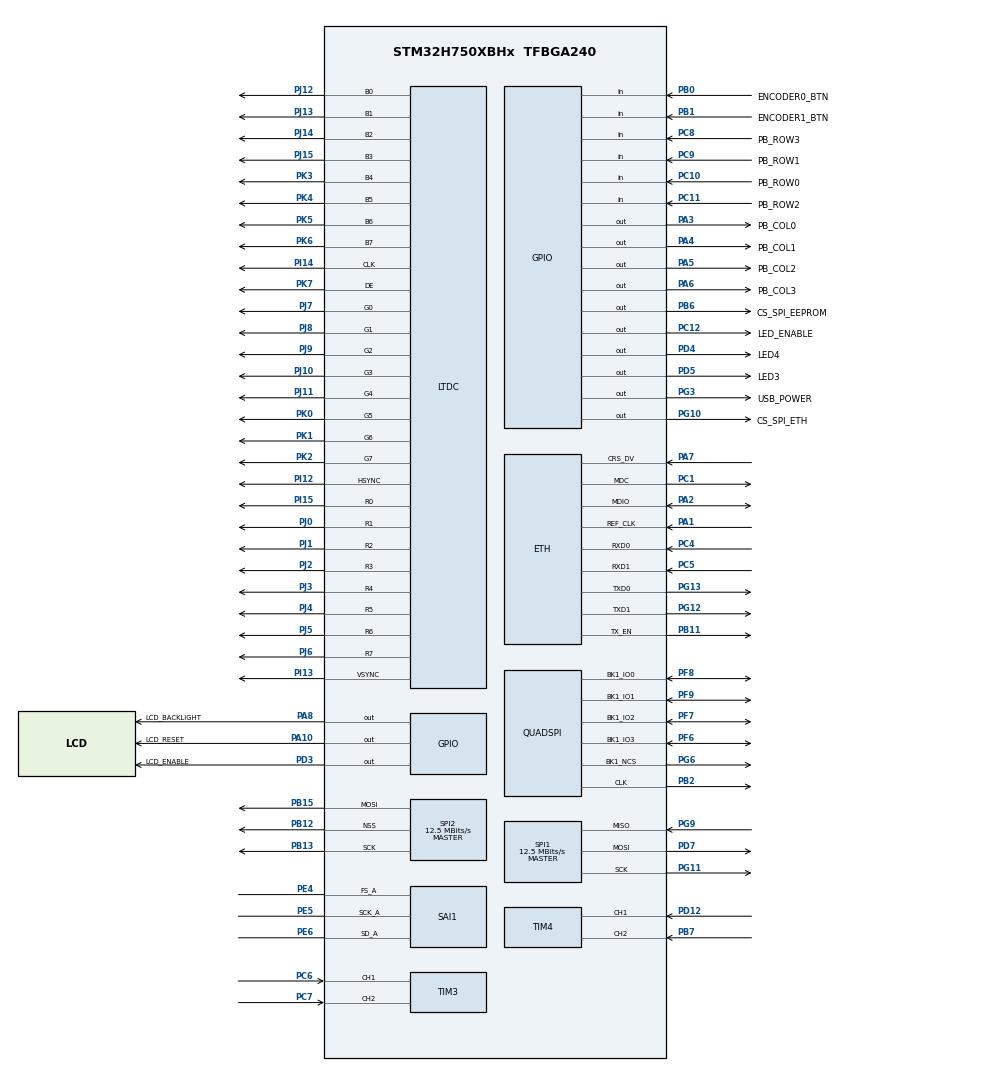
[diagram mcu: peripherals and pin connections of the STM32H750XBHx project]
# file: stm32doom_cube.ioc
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CORTEX_M7.MPU_Control=__NULL
CORTEX_M7.default_mode_Activation=1
DMA2D.ColorMode=DMA2D_OUTPUT_RGB888
DMA2D.Mode=DMA2D_M2M
Dma.Request0=SAI1_A
Dma.SAI1_A.0.Direction=DMA_MEMORY_TO_PERIPH
Dma.SAI1_A.0.EventEnable=DISABLE
Dma.SAI1_A.0.FIFOMode=DMA_FIFOMODE_DISABLE
Dma.SAI1_A.0.Instance=DMA1_Stream4
Dma.SAI1_A.0.MemDataAlignment=DMA_MDATAALIGN_WORD
Dma.SAI1_A.0.MemInc=DMA_MINC_ENABLE
Dma.SAI1_A.0.Mode=DMA_CIRCULAR
Dma.SAI1_A.0.PeriphDataAlignment=DMA_PDATAALIGN_WORD
Dma.SAI1_A.0.PeriphInc=DMA_PINC_DISABLE
Dma.SAI1_A.0.Polarity=HAL_DMAMUX_REQ_GEN_RISING
Dma.SAI1_A.0.Priority=DMA_PRIORITY_HIGH
Dma.SAI1_A.0.RequestNumber=1
Dma.SAI1_A.0.SignalID=NONE
Dma.SAI1_A.0.SyncEnable=DISABLE
Dma.SAI1_A.0.SyncPolarity=HAL_DMAMUX_SYNC_NO_EVENT
Dma.SAI1_A.0.SyncRequestNumber=1
Dma.SAI1_A.0.SyncSignalID=NONE
ETH.ETH_RX_DESC_CNT=8
ETH.ETH_TX_DESC_CNT=4
ETH.MediaInterface=HAL_ETH_RMII_MODE
FATFS._FS_LOCK=0
FATFS._FS_MINIMIZE=0
FATFS._FS_NOFSINFO=0
FATFS._FS_NORTC=0
FATFS._FS_READONLY=1
FATFS._FS_RPATH=2
FATFS._USE_FASTSEEK=1
FATFS._USE_FIND=0
FATFS._USE_LFN=0
FATFS._USE_MKFS=0
FATFS._USE_STRFUNC=2
LTDC.ActiveW=800
LTDC.DEPolarity=LTDC_DEPOLARITY_AL
LTDC.HBP=100
LTDC.HFP=26
LTDC.HSync=75
LTDC.VBP=7
LTDC.VFP=3
LTDC.VSync=11
LWIP.BSP.number=1
LWIP.CHECKSUM_BY_HARDWARE=1
LWIP.IP_ADDRESS=192.168.000.010
LWIP.LWIP_DHCP=0
LWIP.LWIP_NETIF_STATUS_CALLBACK=1
LWIP.LWIP_TCP=0
LWIP.MEM_SIZE=32768
LWIP.NETMASK_ADDRESS=255.255.255.000
LWIP.Version=v2.1.2_Cube
LWIP0.BSP.STBoard=false
LWIP0.BSP.api=BSP_COMPONENT_DRIVER
LWIP0.BSP.component=USER_PHY
LWIP0.BSP.instance=USER_PHY
LWIP0.BSP.name=Driver_PHY
LWIP0.BSP.semaphore=S_USER_PHY
LWIP0.BSP.solution=USER_PHY
Mcu.Family=STM32H7
Mcu.Name=STM32H750XBHx
Mcu.Package=TFBGA240
Mcu.UserConstants=NOSAVE,1
NVIC.DMA1_Stream4_IRQn=true\:0\:0\:false\:false\:true\:false\:true\:true
NVIC.PriorityGroup=NVIC_PRIORITYGROUP_4
PA1.GPIO_Speed=GPIO_SPEED_FREQ_HIGH
PA1.Mode=RMII
PA1.Signal=ETH_REF_CLK
PA10.GPIO_Label=LCD_RESET
PA10.GPIO_ModeDefaultOutputPP=GPIO_MODE_OUTPUT_PP
PA10.GPIO_PuPd=GPIO_NOPULL
PA10.GPIO_Speed=GPIO_SPEED_FREQ_LOW
PA10.PinState=GPIO_PIN_SET
PA10.Signal=GPIO_Output
PA11.GPIO_Speed=GPIO_SPEED_FREQ_MEDIUM
PA11.Signal=USB_OTG_FS_DM
PA12.GPIO_Speed=GPIO_SPEED_FREQ_MEDIUM
PA12.Signal=USB_OTG_FS_DP
PA13\ (JTMS/SWDIO).Mode=JTAG_5_pins
PA13\ (JTMS/SWDIO).Signal=DEBUG_JTMS-SWDIO
PA14\ (JTCK/SWCLK).Mode=JTAG_5_pins
PA14\ (JTCK/SWCLK).Signal=DEBUG_JTCK-SWCLK
PA15\ (JTDI).Mode=JTAG_5_pins
PA15\ (JTDI).Signal=DEBUG_JTDI
PA2.Mode=RMII
PA2.Signal=ETH_MDIO
PA3.GPIO_Label=PB_COL0
PA3.GPIO_ModeDefaultOutputPP=GPIO_MODE_OUTPUT_OD
PA3.GPIO_PuPd=GPIO_NOPULL
PA3.GPIO_Speed=GPIO_SPEED_FREQ_LOW
PA3.PinState=GPIO_PIN_SET
PA3.Signal=GPIO_Output
PA4.GPIO_Label=PB_COL1
PA4.GPIO_ModeDefaultOutputPP=GPIO_MODE_OUTPUT_OD
PA4.GPIO_PuPd=GPIO_NOPULL
PA4.GPIO_Speed=GPIO_SPEED_FREQ_LOW
PA4.PinState=GPIO_PIN_SET
PA4.Signal=GPIO_Output
PA5.GPIO_Label=PB_COL2
PA5.GPIO_ModeDefaultOutputPP=GPIO_MODE_OUTPUT_OD
PA5.GPIO_PuPd=GPIO_NOPULL
PA5.GPIO_Speed=GPIO_SPEED_FREQ_LOW
PA5.PinState=GPIO_PIN_SET
PA5.Signal=GPIO_Output
PA6.GPIO_Label=PB_COL3
PA6.GPIO_ModeDefaultOutputPP=GPIO_MODE_OUTPUT_OD
PA6.GPIO_PuPd=GPIO_NOPULL
PA6.GPIO_Speed=GPIO_SPEED_FREQ_LOW
PA6.PinState=GPIO_PIN_SET
PA6.Signal=GPIO_Output
PA7.GPIO_Speed=GPIO_SPEED_FREQ_HIGH
PA7.Mode=RMII
PA7.Signal=ETH_CRS_DV
PA8.GPIO_Label=LCD_BACKLIGHT
PA8.Signal=GPIO_Output
PA9.Signal=USB_OTG_FS_VBUS
PB0.GPIO_Label=ENCODER0_BTN
PB0.Signal=GPIO_Input
PB1.GPIO_Label=ENCODER1_BTN
PB1.Signal=GPIO_Input
PB11.GPIO_Speed=GPIO_SPEED_FREQ_HIGH
PB11.Mode=RMII
PB11.Signal=ETH_TX_EN
PB12.Mode=NSS_Signal_Hard_Output
PB12.Signal=SPI2_NSS
PB13.Mode=TX_Only_Simplex_Unidirect_Master
PB13.Signal=SPI2_SCK
PB15.Mode=TX_Only_Simplex_Unidirect_Master
PB15.Signal=SPI2_MOSI
PB2.GPIO_Speed=GPIO_SPEED_FREQ_VERY_HIGH
PB2.Mode=Single Bank 1
PB2.Signal=QUADSPI_CLK
PB3\ (JTDO/TRACESWO).Mode=JTAG_5_pins
PB3\ (JTDO/TRACESWO).Signal=DEBUG_JTDO-SWO
PB4\ (NJTRST).Mode=JTAG_5_pins
PB4\ (NJTRST).Signal=DEBUG_JTRST
PB6.GPIO_Label=CS_SPI_EEPROM
PB6.GPIO_Speed=GPIO_SPEED_FREQ_LOW
PB6.PinState=GPIO_PIN_SET
PB6.Signal=GPIO_Output
PB7.Signal=S_TIM4_CH2
PC1.Mode=RMII
PC1.Signal=ETH_MDC
PC10.GPIO_Label=PB_ROW0
PC10.Signal=GPIO_Input
PC11.GPIO_Label=PB_ROW2
PC11.Signal=GPIO_Input
PC12.GPIO_Label=LED_ENABLE
PC12.PinState=GPIO_PIN_SET
PC12.Signal=GPIO_Output
PC14-OSC32_IN\ (OSC32_IN).Mode=LSE-External-Oscillator
PC14-OSC32_IN\ (OSC32_IN).Signal=RCC_OSC32_IN
PC15-OSC32_OUT\ (OSC32_OUT).Mode=LSE-External-Oscillator
PC15-OSC32_OUT\ (OSC32_OUT).Signal=RCC_OSC32_OUT
PC4.GPIO_Speed=GPIO_SPEED_FREQ_HIGH
PC4.Mode=RMII
PC4.Signal=ETH_RXD0
PC5.GPIO_Speed=GPIO_SPEED_FREQ_HIGH
PC5.Mode=RMII
PC5.Signal=ETH_RXD1
PC6.Signal=S_TIM3_CH1
PC7.Signal=S_TIM3_CH2
PC8.GPIO_Label=PB_ROW3
PC8.Signal=GPIO_Input
PC9.GPIO_Label=PB_ROW1
PC9.Signal=GPIO_Input
PD12.Signal=S_TIM4_CH1
PD3.GPIO_Label=LCD_ENABLE
PD3.PinState=GPIO_PIN_SET
PD3.Signal=GPIO_Output
PD4.GPIO_Label=LED4
PD4.PinState=GPIO_PIN_SET
PD4.Signal=GPIO_Output
PD5.GPIO_Label=LED3
PD5.PinState=GPIO_PIN_SET
PD5.Signal=GPIO_Output
PD7.Mode=Full_Duplex_Master
PD7.Signal=SPI1_MOSI
PE4.Mode=SAI_A_Master
PE4.Signal=SAI1_FS_A
PE5.Mode=SAI_A_Master
PE5.Signal=SAI1_SCK_A
PE6.Mode=SAI_A_Master
PE6.Signal=SAI1_SD_A
PF6.GPIO_Speed=GPIO_SPEED_FREQ_VERY_HIGH
PF6.Mode=Single Bank 1
PF6.Signal=QUADSPI_BK1_IO3
PF7.GPIO_Speed=GPIO_SPEED_FREQ_VERY_HIGH
PF7.Mode=Single Bank 1
PF7.Signal=QUADSPI_BK1_IO2
PF8.GPIO_Speed=GPIO_SPEED_FREQ_VERY_HIGH
PF8.Mode=Single Bank 1
PF8.Signal=QUADSPI_BK1_IO0
PF9.GPIO_Speed=GPIO_SPEED_FREQ_VERY_HIGH
PF9.Mode=Single Bank 1
PF9.Signal=QUADSPI_BK1_IO1
PG10.GPIO_Label=CS_SPI_ETH
PG10.GPIO_Speed=GPIO_SPEED_FREQ_LOW
PG10.PinState=GPIO_PIN_SET
PG10.Signal=GPIO_Output
PG11.Mode=Full_Duplex_Master
PG11.Signal=SPI1_SCK
PG12.GPIO_Speed=GPIO_SPEED_FREQ_HIGH
PG12.Mode=RMII
PG12.Signal=ETH_TXD1
PG13.GPIO_Speed=GPIO_SPEED_FREQ_HIGH
PG13.Mode=RMII
PG13.Signal=ETH_TXD0
PG3.GPIO_Label=USB_POWER
PG3.PinState=GPIO_PIN_SET
PG3.Signal=GPIO_Output
PG6.GPIO_Speed=GPIO_SPEED_FREQ_VERY_HIGH
PG6.Mode=Single Bank 1
PG6.Signal=QUADSPI_BK1_NCS
PG9.Mode=Full_Duplex_Master
PG9.Signal=SPI1_MISO
PH0-OSC_IN\ (PH0).Mode=HSE-External-Oscillator
PH0-OSC_IN\ (PH0).Signal=RCC_OSC_IN
PH1-OSC_OUT\ (PH1).Mode=HSE-External-Oscillator
PH1-OSC_OUT\ (PH1).Signal=RCC_OSC_OUT
PI12.GPIO_Speed=GPIO_SPEED_FREQ_MEDIUM
PI12.Mode=RGB888
PI12.Signal=LTDC_HSYNC
PI13.GPIO_Speed=GPIO_SPEED_FREQ_MEDIUM
PI13.Mode=RGB888
PI13.Signal=LTDC_VSYNC
PI14.GPIO_Speed=GPIO_SPEED_FREQ_MEDIUM
PI14.Mode=RGB888
PI14.Signal=LTDC_CLK
PI15.GPIO_Speed=GPIO_SPEED_FREQ_MEDIUM
PI15.Mode=RGB888
PI15.Signal=LTDC_R0
PJ0.GPIO_Speed=GPIO_SPEED_FREQ_MEDIUM
PJ0.Mode=RGB888
PJ0.Signal=LTDC_R1
PJ1.GPIO_Speed=GPIO_SPEED_FREQ_MEDIUM
PJ1.Mode=RGB888
PJ1.Signal=LTDC_R2
PJ10.GPIO_Speed=GPIO_SPEED_FREQ_MEDIUM
PJ10.Mode=RGB888
PJ10.Signal=LTDC_G3
PJ11.GPIO_Speed=GPIO_SPEED_FREQ_MEDIUM
PJ11.Mode=RGB888
PJ11.Signal=LTDC_G4
PJ12.GPIO_Speed=GPIO_SPEED_FREQ_MEDIUM
PJ12.Mode=RGB888
PJ12.Signal=LTDC_B0
PJ13.GPIO_Speed=GPIO_SPEED_FREQ_MEDIUM
PJ13.Mode=RGB888
PJ13.Signal=LTDC_B1
PJ14.GPIO_Speed=GPIO_SPEED_FREQ_MEDIUM
PJ14.Mode=RGB888
PJ14.Signal=LTDC_B2
PJ15.GPIO_Speed=GPIO_SPEED_FREQ_MEDIUM
PJ15.Mode=RGB888
PJ15.Signal=LTDC_B3
PJ2.GPIO_Speed=GPIO_SPEED_FREQ_MEDIUM
PJ2.Mode=RGB888
PJ2.Signal=LTDC_R3
PJ3.GPIO_Speed=GPIO_SPEED_FREQ_MEDIUM
PJ3.Mode=RGB888
PJ3.Signal=LTDC_R4
PJ4.GPIO_Speed=GPIO_SPEED_FREQ_MEDIUM
PJ4.Mode=RGB888
PJ4.Signal=LTDC_R5
PJ5.GPIO_Speed=GPIO_SPEED_FREQ_MEDIUM
PJ5.Mode=RGB888
PJ5.Signal=LTDC_R6
PJ6.GPIO_Speed=GPIO_SPEED_FREQ_MEDIUM
PJ6.Mode=RGB888
PJ6.Signal=LTDC_R7
PJ7.GPIO_Speed=GPIO_SPEED_FREQ_MEDIUM
PJ7.Mode=RGB888
PJ7.Signal=LTDC_G0
PJ8.GPIO_Speed=GPIO_SPEED_FREQ_MEDIUM
PJ8.Mode=RGB888
PJ8.Signal=LTDC_G1
PJ9.GPIO_Speed=GPIO_SPEED_FREQ_MEDIUM
PJ9.Mode=RGB888
PJ9.Signal=LTDC_G2
PK0.GPIO_Speed=GPIO_SPEED_FREQ_MEDIUM
PK0.Mode=RGB888
PK0.Signal=LTDC_G5
PK1.GPIO_Speed=GPIO_SPEED_FREQ_MEDIUM
PK1.Mode=RGB888
PK1.Signal=LTDC_G6
PK2.GPIO_Speed=GPIO_SPEED_FREQ_MEDIUM
PK2.Mode=RGB888
PK2.Signal=LTDC_G7
PK3.GPIO_Speed=GPIO_SPEED_FREQ_MEDIUM
PK3.Mode=RGB888
PK3.Signal=LTDC_B4
PK4.GPIO_Speed=GPIO_SPEED_FREQ_MEDIUM
PK4.Mode=RGB888
PK4.Signal=LTDC_B5
PK5.GPIO_Speed=GPIO_SPEED_FREQ_MEDIUM
PK5.Mode=RGB888
PK5.Signal=LTDC_B6
PK6.GPIO_Speed=GPIO_SPEED_FREQ_MEDIUM
PK6.Mode=RGB888
PK6.Signal=LTDC_B7
PK7.GPIO_Speed=GPIO_SPEED_FREQ_MEDIUM
PK7.Mode=RGB888
PK7.Signal=LTDC_DE
ProjectManager.HeapSize=0x200
ProjectManager.StackSize=0x400
ProjectManager.TargetToolchain=CMake
QUADSPI.ChipSelectHighTime=QSPI_CS_HIGH_TIME_5_CYCLE
QUADSPI.ClockPrescaler=1
QUADSPI.FlashSize=25
QUADSPI.SampleShifting=QSPI_SAMPLE_SHIFTING_HALFCYCLE
RCC.ADCFreq_Value=90316813.15104167
RCC.APB1Freq_Value=100000000
RCC.APB2Freq_Value=100000000
RCC.APB3Freq_Value=100000000
RCC.APB4Freq_Value=100000000
RCC.CortexFreq_Value=400000000
RCC.D1PPRE=RCC_APB3_DIV2
RCC.D2PPRE1=RCC_APB1_DIV2
RCC.D2PPRE2=RCC_APB2_DIV2
RCC.D3PPRE=RCC_APB4_DIV2
RCC.DIVM1=5
RCC.DIVM2=25
RCC.DIVM3=2
RCC.DIVN1=160
RCC.DIVN2=270
RCC.DIVN3=12
RCC.DIVP2=3
RCC.DIVQ1=8
RCC.DIVR3=5
RCC.HCLKFreq_Value=200000000
RCC.HPRE=RCC_HCLK_DIV2
RCC.PLL2FRACN=7786
RCC.PLL3FRACN=0
RCC.PLLFRACN=0
RCC.PLLSourceVirtual=RCC_PLLSOURCE_HSE
RCC.SAI1CLockSelection=RCC_SAI1CLKSOURCE_PLL2
RCC.SYSCLKFreq_VALUE=400000000
RCC.SYSCLKSource=RCC_SYSCLKSOURCE_PLLCLK
RCC.USBCLockSelection=RCC_USBCLKSOURCE_HSI48
RCC.USBFreq_Value=48000000
SAI1.AudioFrequency-SAI_A_Master=SAI_AUDIO_FREQUENCY_44K
SAI1.CompandingMode-SAI_A_Master=SAI_NOCOMPANDING
SAI1.ErrorAudioFreq-SAI_A_Master=700.0 %
SAI1.FIFOThreshold-SAI_A_Master=SAI_FIFOTHRESHOLD_HF
SAI1.InitProtocol-SAI_A_Master=Enable
SAI1.Instance-SAI_A_Master=SAI$Index_Block_A
SAI1.MClockEnable-SAI_A_Master=SAI_MASTERCLOCK_DISABLE
SAI1.MckOverSampling-SAI_A_Master=SAI_MCK_OVERSAMPLING_ENABLE
SAI1.NoDivider-SAI_A_Master=SAI_MCK_OVERSAMPLING_DISABLE
SAI1.OutputDrive-SAI_A_Master=SAI_OUTPUTDRIVE_ENABLE
SAI1.RealAudioFreq-SAI_A_Master=352.8 KHz
SAI1.VirtualMode-SAI_A_Master=VM_MASTER
SAI1.VirtualProtocol-SAI_A_BASIC=VM_BASIC_PROTOCOL
SH.S_TIM3_CH1.0=TIM3_CH1,Encoder_Interface
SH.S_TIM3_CH2.0=TIM3_CH2,Encoder_Interface
SH.S_TIM4_CH1.0=TIM4_CH1,Encoder_Interface
SH.S_TIM4_CH2.0=TIM4_CH2,Encoder_Interface
SPI1.BaudRatePrescaler=SPI_BAUDRATEPRESCALER_8
SPI1.CalculateBaudRate=12.5 MBits/s
SPI1.DataSize=SPI_DATASIZE_8BIT
SPI1.Direction=SPI_DIRECTION_2LINES
SPI1.Mode=SPI_MODE_MASTER
SPI1.VirtualType=VM_MASTER
SPI2.BaudRatePrescaler=SPI_BAUDRATEPRESCALER_8
SPI2.CLKPhase=SPI_PHASE_2EDGE
SPI2.CLKPolarity=SPI_POLARITY_HIGH
SPI2.CRCCalculation=SPI_CRCCALCULATION_DISABLE
SPI2.CalculateBaudRate=12.5 MBits/s
SPI2.DataSize=SPI_DATASIZE_16BIT
SPI2.Direction=SPI_DIRECTION_2LINES_TXONLY
SPI2.Mode=SPI_MODE_MASTER
SPI2.NSSPMode=SPI_NSS_PULSE_ENABLE
SPI2.TIMode=SPI_TIMODE_DISABLE
SPI2.VirtualNSS=VM_NSSHARD
SPI2.VirtualType=VM_MASTER
VP_DMA2D_VS_DMA2D.Mode=DMA2D_Activate
VP_FATFS_VS_Generic.Mode=User_defined
VP_LWIP_VS_Enabled.Mode=Enabled
VP_MEMORYMAP_VS_MEMORYMAP.Mode=CurAppReg
VP_SAI1_VP_$IpInstance_SAIA_SAI_BASIC.Mode=SAI_A_BASIC
board=custom

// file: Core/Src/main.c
/* USER CODE BEGIN Header */
/**
  ******************************************************************************
  * @file           : main.c
  * @brief          : Main program body
  ******************************************************************************
  * @attention
  *
  * Copyright (c) 2025 STMicroelectronics.
  * All rights reserved.
  *
  * This software is licensed under terms that can be found in the LICENSE file
  * in the root directory of this software component.
  * If no LICENSE file comes with this software, it is provided AS-IS.
  *
  ******************************************************************************
  */
/* USER CODE END Header */
#include "main.h"
#include "fatfs.h"
#include "lwip.h"

/* USER CODE BEGIN Includes */
#include <stdio.h>
#include <string.h>

#include "gfx.h"
#include "images.h"
#include "jpeg.h"
#include "lcd.h"
#include "ksz8863.h"
#include "inputoutput.h"

// Doom command line arguments (avoid including m_argv.h due to type conflicts)
extern int myargc;
extern char **myargv;

// Static storage for command line arguments
#define MAX_ARGS 10
static char *argv_storage[MAX_ARGS];

/* USER CODE END Includes */

DMA2D_HandleTypeDef hdma2d;

LTDC_HandleTypeDef hltdc;

QSPI_HandleTypeDef hqspi;

void SystemClock_Config(void);
void PeriphCommonClock_Config(void);
static void MX_GPIO_Init(void);
static void MX_LTDC_Init(void);
static void MX_QUADSPI_Init(void);
static void MX_SPI1_Init(void);
static void MX_SPI2_Init(void);
static void MX_TIM3_Init(void);
static void MX_TIM4_Init(void);
static void MX_DMA2D_Init(void);
/* USER CODE BEGIN PFP */
void ITM_Init(void);
extern void D_DoomMain (void);
/* USER CODE END PFP */

/* USER CODE BEGIN 0 */

//
// Configure network mode based on button held at startup
// Button layout (from inputoutput.h):
//   ESC (bit 0): Single player (default)
//   F11 (bit 1): Start as server
//   '1' (bit 2): Join as client
//
static void ConfigureNetworkMode(void)
{
    uint16_t buttons;
    extern struct netif gnetif;
    char ip_str[16];

    // Initialize argv array
    myargv = argv_storage;
    myargc = 1;
    argv_storage[0] = "doom";  // Program name

    // Wait a moment for buttons to settle
    HAL_Delay(100);

    // Read button state
    buttonMatrixScan();
    HAL_Delay(10);
    buttonMatrixScan();
    buttons = getButtonMatrix();

    // Get our IP address for display
    snprintf(ip_str, sizeof(ip_str), "%s", ip4addr_ntoa(netif_ip4_addr(&gnetif)));

    if (buttons & BUTTON_T4) {
        printf("=================================\n");
        printf("  DOOM COOPERATIVE - SERVER MODE\n");
        printf("  IP Address: %s\n", ip_str);
        printf("  Port: 2342\n");
        printf("=================================\n");
        myargv[myargc] = "-server";
        printf("DEBUG: Set myargv[%d] = '%s'\n", myargc, myargv[myargc]);
        myargc++;
    } else if (buttons & BUTTON_T5) {
        printf("=================================\n");
        printf("  DOOM DEATHMATCH - SERVER MODE\n");
        printf("  IP Address: %s\n", ip_str);
        printf("  Port: 2342\n");
        printf("=================================\n");
        myargv[myargc] = "-server";
        printf("DEBUG: Set myargv[%d] = '%s'\n", myargc, myargv[myargc]);
        myargc++;
        myargv[myargc] = "-altdeath";
        printf("DEBUG: Set myargv[%d] = '%s'\n", myargc, myargv[myargc]);
        myargc++;
        myargv[myargc] = "-nomonsters";
        printf("DEBUG: Set myargv[%d] = '%s'\n", myargc, myargv[myargc]);
        myargc++;
    } else if (buttons & BUTTON_1) {
        // TODO: Make server IP configurable via config file
        static char server_arg[20] = "192.168.0.10";

        printf("=================================\n");
        printf("  DOOM MULTIPLAYER - CLIENT MODE\n");
        printf("  Our IP: %s\n", ip_str);
        printf("  Connecting to: %s:2342\n", server_arg);
        printf("=================================\n");
        myargv[myargc] = "-connect";
        printf("DEBUG: Set myargv[%d] = '%s'\n", myargc, myargv[myargc]);
        myargc++;
        myargv[myargc] = server_arg;
        printf("DEBUG: Set myargv[%d] = '%s'\n", myargc, myargv[myargc]);
        myargc++;

    } else {
        // No button held - SINGLE PLAYER
        printf("=================================\n");
        printf("  DOOM - SINGLE PLAYER MODE\n");
        printf("=================================\n");
    }

    // Debug: print all arguments
    printf("DEBUG: Total arguments = %d\n", myargc);
    for (int i = 0; i < myargc; i++) {
        printf("  myargv[%d] = '%s'\n", i, myargv[i]);
    }
}

/*
 * Show fatal error message and stop in endless loop
 */
void fatal_error (const char* message)
{
    printf ("FATAL ERROR: %s\n", message);

    while (1)
    {
    }
}

static void show_image (const uint8_t* img)
{
    gfx_image_t title;
    gfx_obj_t obj_title;

    title.width = 240;
    title.height = 320;
    title.pixel_format = GFX_PIXEL_FORMAT_RGB565;
    title.pixel_data = malloc (title.width * title.height * 2);
    if (title.pixel_data == NULL)
    {
        fatal_error("Cannot allocate memory.");
    }

    obj_title.obj_type = GFX_OBJ_IMG;
    obj_title.coords.dest_x = 0;
    obj_title.coords.dest_y = 0;
    obj_title.coords.source_x = 0;
    obj_title.coords.source_y = 0;
    obj_title.coords.source_w = title.width;
    obj_title.coords.source_h = title.height;
    obj_title.data = &title;

    jpeg_decode ((uint8_t*)img, title.pixel_data, 0, 0);

    gfx_objects[0] = &obj_title;

    gfx_draw_objects ();

    LL_mDelay(500);

    gfx_delete_objects ();

    free (title.pixel_data);
}

/* USER CODE END 0 */

int main(void)
{

  /* MCU Configuration--------------------------------------------------------*/

  /* Reset of all peripherals, Initializes the Flash interface and the Systick. */
  HAL_Init();

  /* Configure the system clock */
  SystemClock_Config();

  /* Configure the peripherals common clocks */
  PeriphCommonClock_Config();

  /* USER CODE BEGIN SysInit */
  __enable_irq();
  /* USER CODE END SysInit */

  /* Initialize all configured peripherals */
  MX_GPIO_Init();
  MX_LTDC_Init();
  MX_QUADSPI_Init();
  MX_SPI1_Init();
  MX_SPI2_Init();
  MX_TIM3_Init();
  MX_TIM4_Init();
  MX_FATFS_Init();
  MX_DMA2D_Init();
  MX_LWIP_Init();
  /* USER CODE BEGIN 2 */
    ITM_Init();

    gfx_init();

    FATFS fs;
    FRESULT res = f_mount(&fs, "0", 1);
    if (res != FR_OK)
    {
        printf("Could not mount drive with result %d.\n", res);
        while (1);
    }

  /* USER CODE END 2 */

  /* Infinite loop */
  /* USER CODE BEGIN WHILE */
    // Configure network mode based on startup button
    ConfigureNetworkMode();

    D_DoomMain();
  while (1)
  {
      // Should never get here
  }
    /* USER CODE END WHILE */

}

void SystemClock_Config(void)
{
  LL_FLASH_SetLatency(LL_FLASH_LATENCY_2);
  while(LL_FLASH_GetLatency()!= LL_FLASH_LATENCY_2)
  {
  }
  LL_PWR_ConfigSupply(LL_PWR_LDO_SUPPLY);
  LL_PWR_SetRegulVoltageScaling(LL_PWR_REGU_VOLTAGE_SCALE1);
  while (LL_PWR_IsActiveFlag_VOS() == 0)
  {
  }
  LL_RCC_HSE_Enable();

   /* Wait till HSE is ready */
  while(LL_RCC_HSE_IsReady() != 1)
  {

  }
  LL_RCC_PLL_SetSource(LL_RCC_PLLSOURCE_HSE);
  LL_RCC_PLL1P_Enable();
  LL_RCC_PLL1Q_Enable();
  LL_RCC_PLL1R_Enable();
  LL_RCC_PLL1_SetVCOInputRange(LL_RCC_PLLINPUTRANGE_4_8);
  LL_RCC_PLL1_SetVCOOutputRange(LL_RCC_PLLVCORANGE_WIDE);
  LL_RCC_PLL1_SetM(5);
  LL_RCC_PLL1_SetN(160);
  LL_RCC_PLL1_SetP(2);
  LL_RCC_PLL1_SetQ(8);
  LL_RCC_PLL1_SetR(2);
  LL_RCC_PLL1_Enable();

   /* Wait till PLL is ready */
  while(LL_RCC_PLL1_IsReady() != 1)
  {
  }

   /* Intermediate AHB prescaler 2 when target frequency clock is higher than 80 MHz */
   LL_RCC_SetAHBPrescaler(LL_RCC_AHB_DIV_2);

  LL_RCC_SetSysClkSource(LL_RCC_SYS_CLKSOURCE_PLL1);

   /* Wait till System clock is ready */
  while(LL_RCC_GetSysClkSource() != LL_RCC_SYS_CLKSOURCE_STATUS_PLL1)
  {

  }
  LL_RCC_SetSysPrescaler(LL_RCC_SYSCLK_DIV_1);
  LL_RCC_SetAHBPrescaler(LL_RCC_AHB_DIV_2);
  LL_RCC_SetAPB1Prescaler(LL_RCC_APB1_DIV_2);
  LL_RCC_SetAPB2Prescaler(LL_RCC_APB2_DIV_2);
  LL_RCC_SetAPB3Prescaler(LL_RCC_APB3_DIV_2);
  LL_RCC_SetAPB4Prescaler(LL_RCC_APB4_DIV_2);
  LL_SetSystemCoreClock(400000000);

   /* Update the time base */
  if (HAL_InitTick (TICK_INT_PRIORITY) != HAL_OK)
  {
    Error_Handler();
  }
}

void PeriphCommonClock_Config(void)
{
  LL_RCC_PLL3R_Enable();
  LL_RCC_PLL3_SetVCOInputRange(LL_RCC_PLLINPUTRANGE_8_16);
  LL_RCC_PLL3_SetVCOOutputRange(LL_RCC_PLLVCORANGE_MEDIUM);
  LL_RCC_PLL3_SetM(2);
  LL_RCC_PLL3_SetN(12);
  LL_RCC_PLL3_SetP(2);
  LL_RCC_PLL3_SetQ(2);
  LL_RCC_PLL3_SetR(5);
  LL_RCC_PLL3_Enable();

   /* Wait till PLL is ready */
  while(LL_RCC_PLL3_IsReady() != 1)
  {
  }

}

static void MX_DMA2D_Init(void)
{

  hdma2d.Instance = DMA2D;
  hdma2d.Init.Mode = DMA2D_M2M;
  hdma2d.Init.ColorMode = DMA2D_OUTPUT_RGB888;
  hdma2d.Init.OutputOffset = 0;
  hdma2d.LayerCfg[1].InputOffset = 0;
  hdma2d.LayerCfg[1].InputColorMode = DMA2D_INPUT_RGB888;
  hdma2d.LayerCfg[1].AlphaMode = DMA2D_NO_MODIF_ALPHA;
  hdma2d.LayerCfg[1].InputAlpha = 0;
  hdma2d.LayerCfg[1].AlphaInverted = DMA2D_REGULAR_ALPHA;
  hdma2d.LayerCfg[1].RedBlueSwap = DMA2D_RB_REGULAR;
  hdma2d.LayerCfg[1].ChromaSubSampling = DMA2D_NO_CSS;
  if (HAL_DMA2D_Init(&hdma2d) != HAL_OK)
  {
    Error_Handler();
  }
  if (HAL_DMA2D_ConfigLayer(&hdma2d, 1) != HAL_OK)
  {
    Error_Handler();
  }

}

static void MX_LTDC_Init(void)
{

  LTDC_LayerCfgTypeDef pLayerCfg = {0};
  LTDC_LayerCfgTypeDef pLayerCfg1 = {0};

  hltdc.Instance = LTDC;
  hltdc.Init.HSPolarity = LTDC_HSPOLARITY_AL;
  hltdc.Init.VSPolarity = LTDC_VSPOLARITY_AL;
  hltdc.Init.DEPolarity = LTDC_DEPOLARITY_AL;
  hltdc.Init.PCPolarity = LTDC_PCPOLARITY_IPC;
  hltdc.Init.HorizontalSync = 74;
  hltdc.Init.VerticalSync = 10;
  hltdc.Init.AccumulatedHBP = 174;
  hltdc.Init.AccumulatedVBP = 17;
  hltdc.Init.AccumulatedActiveW = 974;
  hltdc.Init.AccumulatedActiveH = 497;
  hltdc.Init.TotalWidth = 1000;
  hltdc.Init.TotalHeigh = 500;
  hltdc.Init.Backcolor.Blue = 0;
  hltdc.Init.Backcolor.Green = 0;
  hltdc.Init.Backcolor.Red = 0;
  if (HAL_LTDC_Init(&hltdc) != HAL_OK)
  {
    Error_Handler();
  }
  pLayerCfg.WindowX0 = 0;
  pLayerCfg.WindowX1 = 0;
  pLayerCfg.WindowY0 = 0;
  pLayerCfg.WindowY1 = 0;
  pLayerCfg.PixelFormat = LTDC_PIXEL_FORMAT_ARGB8888;
  pLayerCfg.Alpha = 0;
  pLayerCfg.Alpha0 = 0;
  pLayerCfg.BlendingFactor1 = LTDC_BLENDING_FACTOR1_CA;
  pLayerCfg.BlendingFactor2 = LTDC_BLENDING_FACTOR2_CA;
  pLayerCfg.FBStartAdress = 0;
  pLayerCfg.ImageWidth = 0;
  pLayerCfg.ImageHeight = 0;
  pLayerCfg.Backcolor.Blue = 0;
  pLayerCfg.Backcolor.Green = 0;
  pLayerCfg.Backcolor.Red = 0;
  if (HAL_LTDC_ConfigLayer(&hltdc, &pLayerCfg, 0) != HAL_OK)
  {
    Error_Handler();
  }
  pLayerCfg1.WindowX0 = 0;
  pLayerCfg1.WindowX1 = 0;
  pLayerCfg1.WindowY0 = 0;
  pLayerCfg1.WindowY1 = 0;
  pLayerCfg1.PixelFormat = LTDC_PIXEL_FORMAT_ARGB8888;
  pLayerCfg1.Alpha = 0;
  pLayerCfg1.Alpha0 = 0;
  pLayerCfg1.BlendingFactor1 = LTDC_BLENDING_FACTOR1_CA;
  pLayerCfg1.BlendingFactor2 = LTDC_BLENDING_FACTOR2_CA;
  pLayerCfg1.FBStartAdress = 0;
  pLayerCfg1.ImageWidth = 0;
  pLayerCfg1.ImageHeight = 0;
  pLayerCfg1.Backcolor.Blue = 0;
  pLayerCfg1.Backcolor.Green = 0;
  pLayerCfg1.Backcolor.Red = 0;
  if (HAL_LTDC_ConfigLayer(&hltdc, &pLayerCfg1, 1) != HAL_OK)
  {
    Error_Handler();
  }
  /* USER CODE BEGIN LTDC_Init 2 */
    HAL_NVIC_SetPriority(LTDC_IRQn, 6, 0);
    HAL_NVIC_EnableIRQ(LTDC_IRQn);
    lcd_init();
  /* USER CODE END LTDC_Init 2 */

}

static void MX_QUADSPI_Init(void)
{

  /* USER CODE BEGIN QUADSPI_Init 0 */
    // Make sure it's been deinitialized, since it was running in the bootloader and could be in a bad state
    memset(&hqspi, 0, sizeof(hqspi));
    hqspi.Instance = QUADSPI;
    if (HAL_QSPI_DeInit(&hqspi) != HAL_OK)
    {
        Error_Handler();
    }

  /* USER CODE END QUADSPI_Init 0 */

  /* QUADSPI parameter configuration*/
  hqspi.Instance = QUADSPI;
  hqspi.Init.ClockPrescaler = 1;
  hqspi.Init.FifoThreshold = 1;
  hqspi.Init.SampleShifting = QSPI_SAMPLE_SHIFTING_HALFCYCLE;
  hqspi.Init.FlashSize = 25;
  hqspi.Init.ChipSelectHighTime = QSPI_CS_HIGH_TIME_5_CYCLE;
  hqspi.Init.ClockMode = QSPI_CLOCK_MODE_0;
  hqspi.Init.FlashID = QSPI_FLASH_ID_1;
  hqspi.Init.DualFlash = QSPI_DUALFLASH_DISABLE;
  if (HAL_QSPI_Init(&hqspi) != HAL_OK)
  {
    Error_Handler();
  }
  /* USER CODE BEGIN QUADSPI_Init 2 */

    // Reset the Flash to simplest mode

    QSPI_CommandTypeDef cmd;
    cmd.DummyCycles = 0;
    cmd.InstructionMode = QSPI_INSTRUCTION_4_LINES;
    cmd.AddressMode = QSPI_ADDRESS_NONE;
    cmd.AlternateByteMode = QSPI_ALTERNATE_BYTES_NONE;
    cmd.DataMode = QSPI_DATA_NONE;
    cmd.DdrMode = QSPI_DDR_MODE_DISABLE;
    cmd.SIOOMode = QSPI_SIOO_INST_EVERY_CMD;

    cmd.Instruction = 0x66;
    if (HAL_QSPI_Command(&hqspi, &cmd, 1000) != HAL_OK)
    {
        printf("QSPI Reset Enable command failed!\n");
    }

    cmd.Instruction = 0x99;
    if (HAL_QSPI_Command(&hqspi, &cmd, 1000) != HAL_OK)
    {
        printf("QSPI Reset Memory command failed!\n");
    }

    cmd.InstructionMode = QSPI_INSTRUCTION_2_LINES;
    cmd.Instruction = 0x66;
    if (HAL_QSPI_Command(&hqspi, &cmd, 1000) != HAL_OK)
    {
        printf("QSPI Reset Enable command failed!\n");
    }

    cmd.Instruction = 0x99;
    if (HAL_QSPI_Command(&hqspi, &cmd, 1000) != HAL_OK)
    {
        printf("QSPI Reset Memory command failed!\n");
    }

  /* USER CODE END QUADSPI_Init 2 */

}

static void MX_SPI1_Init(void)
{

  LL_SPI_InitTypeDef SPI_InitStruct = {0};

  LL_GPIO_InitTypeDef GPIO_InitStruct = {0};

  LL_RCC_SetSPIClockSource(LL_RCC_SPI123_CLKSOURCE_PLL1Q);

  /* Peripheral clock enable */
  LL_APB2_GRP1_EnableClock(LL_APB2_GRP1_PERIPH_SPI1);

  LL_AHB4_GRP1_EnableClock(LL_AHB4_GRP1_PERIPH_GPIOG);
  LL_AHB4_GRP1_EnableClock(LL_AHB4_GRP1_PERIPH_GPIOD);
  /**SPI1 GPIO Configuration
  PG9   ------> SPI1_MISO
  PG11   ------> SPI1_SCK
  PD7   ------> SPI1_MOSI
  */
  GPIO_InitStruct.Pin = LL_GPIO_PIN_9|LL_GPIO_PIN_11;
  GPIO_InitStruct.Mode = LL_GPIO_MODE_ALTERNATE;
  GPIO_InitStruct.Speed = LL_GPIO_SPEED_FREQ_LOW;
  GPIO_InitStruct.OutputType = LL_GPIO_OUTPUT_PUSHPULL;
  GPIO_InitStruct.Pull = LL_GPIO_PULL_NO;
  GPIO_InitStruct.Alternate = LL_GPIO_AF_5;
  LL_GPIO_Init(GPIOG, &GPIO_InitStruct);

  GPIO_InitStruct.Pin = LL_GPIO_PIN_7;
  GPIO_InitStruct.Mode = LL_GPIO_MODE_ALTERNATE;
  GPIO_InitStruct.Speed = LL_GPIO_SPEED_FREQ_LOW;
  GPIO_InitStruct.OutputType = LL_GPIO_OUTPUT_PUSHPULL;
  GPIO_InitStruct.Pull = LL_GPIO_PULL_NO;
  GPIO_InitStruct.Alternate = LL_GPIO_AF_5;
  LL_GPIO_Init(GPIOD, &GPIO_InitStruct);

  /* SPI1 parameter configuration*/
  SPI_InitStruct.TransferDirection = LL_SPI_FULL_DUPLEX;
  SPI_InitStruct.Mode = LL_SPI_MODE_MASTER;
  SPI_InitStruct.DataWidth = LL_SPI_DATAWIDTH_8BIT;
  SPI_InitStruct.ClockPolarity = LL_SPI_POLARITY_LOW;
  SPI_InitStruct.ClockPhase = LL_SPI_PHASE_1EDGE;
  SPI_InitStruct.NSS = LL_SPI_NSS_SOFT;
  SPI_InitStruct.BaudRate = LL_SPI_BAUDRATEPRESCALER_DIV8;
  SPI_InitStruct.BitOrder = LL_SPI_MSB_FIRST;
  SPI_InitStruct.CRCCalculation = LL_SPI_CRCCALCULATION_DISABLE;
  SPI_InitStruct.CRCPoly = 0x0;
  LL_SPI_Init(SPI1, &SPI_InitStruct);
  LL_SPI_SetStandard(SPI1, LL_SPI_PROTOCOL_MOTOROLA);
  LL_SPI_SetFIFOThreshold(SPI1, LL_SPI_FIFO_TH_01DATA);
  LL_SPI_EnableNSSPulseMgt(SPI1);
  /* USER CODE BEGIN SPI1_Init 2 */
  LL_SPI_Enable(SPI1);
  /* USER CODE END SPI1_Init 2 */

}

static void MX_SPI2_Init(void)
{

  LL_SPI_InitTypeDef SPI_InitStruct = {0};

  LL_GPIO_InitTypeDef GPIO_InitStruct = {0};

  LL_RCC_SetSPIClockSource(LL_RCC_SPI123_CLKSOURCE_PLL1Q);

  /* Peripheral clock enable */
  LL_APB1_GRP1_EnableClock(LL_APB1_GRP1_PERIPH_SPI2);

  LL_AHB4_GRP1_EnableClock(LL_AHB4_GRP1_PERIPH_GPIOB);
  /**SPI2 GPIO Configuration
  PB12   ------> SPI2_NSS
  PB15   ------> SPI2_MOSI
  PB13   ------> SPI2_SCK
  */
  GPIO_InitStruct.Pin = LL_GPIO_PIN_12|LL_GPIO_PIN_15|LL_GPIO_PIN_13;
  GPIO_InitStruct.Mode = LL_GPIO_MODE_ALTERNATE;
  GPIO_InitStruct.Speed = LL_GPIO_SPEED_FREQ_LOW;
  GPIO_InitStruct.OutputType = LL_GPIO_OUTPUT_PUSHPULL;
  GPIO_InitStruct.Pull = LL_GPIO_PULL_NO;
  GPIO_InitStruct.Alternate = LL_GPIO_AF_5;
  LL_GPIO_Init(GPIOB, &GPIO_InitStruct);

  /* SPI2 parameter configuration*/
  SPI_InitStruct.TransferDirection = LL_SPI_SIMPLEX_TX;
  SPI_InitStruct.Mode = LL_SPI_MODE_MASTER;
  SPI_InitStruct.DataWidth = LL_SPI_DATAWIDTH_16BIT;
  SPI_InitStruct.ClockPolarity = LL_SPI_POLARITY_HIGH;
  SPI_InitStruct.ClockPhase = LL_SPI_PHASE_2EDGE;
  SPI_InitStruct.NSS = LL_SPI_NSS_HARD_OUTPUT;
  SPI_InitStruct.BaudRate = LL_SPI_BAUDRATEPRESCALER_DIV8;
  SPI_InitStruct.BitOrder = LL_SPI_MSB_FIRST;
  SPI_InitStruct.CRCCalculation = LL_SPI_CRCCALCULATION_DISABLE;
  SPI_InitStruct.CRCPoly = 0x0;
  LL_SPI_Init(SPI2, &SPI_InitStruct);
  LL_SPI_SetStandard(SPI2, LL_SPI_PROTOCOL_MOTOROLA);
  LL_SPI_SetFIFOThreshold(SPI2, LL_SPI_FIFO_TH_01DATA);
  LL_SPI_EnableNSSPulseMgt(SPI2);
  /* USER CODE BEGIN SPI2_Init 2 */
    LL_SPI_Enable(SPI2);
    LL_GPIO_ResetOutputPin(LED_ENABLE_GPIO_Port, LED_ENABLE_Pin);
  /* USER CODE END SPI2_Init 2 */

}

static void MX_TIM3_Init(void)
{

  LL_TIM_InitTypeDef TIM_InitStruct = {0};

  LL_GPIO_InitTypeDef GPIO_InitStruct = {0};

  /* Peripheral clock enable */
  LL_APB1_GRP1_EnableClock(LL_APB1_GRP1_PERIPH_TIM3);

  LL_AHB4_GRP1_EnableClock(LL_AHB4_GRP1_PERIPH_GPIOC);
  /**TIM3 GPIO Configuration
  PC7   ------> TIM3_CH2
  PC6   ------> TIM3_CH1
  */
  GPIO_InitStruct.Pin = LL_GPIO_PIN_7|LL_GPIO_PIN_6;
  GPIO_InitStruct.Mode = LL_GPIO_MODE_ALTERNATE;
  GPIO_InitStruct.Speed = LL_GPIO_SPEED_FREQ_LOW;
  GPIO_InitStruct.OutputType = LL_GPIO_OUTPUT_PUSHPULL;
  GPIO_InitStruct.Pull = LL_GPIO_PULL_NO;
  GPIO_InitStruct.Alternate = LL_GPIO_AF_2;
  LL_GPIO_Init(GPIOC, &GPIO_InitStruct);

  TIM_InitStruct.Prescaler = 0;
  TIM_InitStruct.CounterMode = LL_TIM_COUNTERMODE_UP;
  TIM_InitStruct.Autoreload = 65535;
  TIM_InitStruct.ClockDivision = LL_TIM_CLOCKDIVISION_DIV1;
  LL_TIM_Init(TIM3, &TIM_InitStruct);
  LL_TIM_DisableARRPreload(TIM3);
  LL_TIM_SetEncoderMode(TIM3, LL_TIM_ENCODERMODE_X2_TI1);
  LL_TIM_IC_SetActiveInput(TIM3, LL_TIM_CHANNEL_CH1, LL_TIM_ACTIVEINPUT_DIRECTTI);
  LL_TIM_IC_SetPrescaler(TIM3, LL_TIM_CHANNEL_CH1, LL_TIM_ICPSC_DIV1);
  LL_TIM_IC_SetFilter(TIM3, LL_TIM_CHANNEL_CH1, LL_TIM_IC_FILTER_FDIV1);
  LL_TIM_IC_SetPolarity(TIM3, LL_TIM_CHANNEL_CH1, LL_TIM_IC_POLARITY_RISING);
  LL_TIM_IC_SetActiveInput(TIM3, LL_TIM_CHANNEL_CH2, LL_TIM_ACTIVEINPUT_DIRECTTI);
  LL_TIM_IC_SetPrescaler(TIM3, LL_TIM_CHANNEL_CH2, LL_TIM_ICPSC_DIV1);
  LL_TIM_IC_SetFilter(TIM3, LL_TIM_CHANNEL_CH2, LL_TIM_IC_FILTER_FDIV1);
  LL_TIM_IC_SetPolarity(TIM3, LL_TIM_CHANNEL_CH2, LL_TIM_IC_POLARITY_RISING);
  LL_TIM_SetTriggerOutput(TIM3, LL_TIM_TRGO_RESET);
  LL_TIM_DisableMasterSlaveMode(TIM3);
  /* USER CODE BEGIN TIM3_Init 2 */
    LL_TIM_EnableCounter(TIM3);
  /* USER CODE END TIM3_Init 2 */

}

static void MX_TIM4_Init(void)
{

  LL_TIM_InitTypeDef TIM_InitStruct = {0};

  LL_GPIO_InitTypeDef GPIO_InitStruct = {0};

  /* Peripheral clock enable */
  LL_APB1_GRP1_EnableClock(LL_APB1_GRP1_PERIPH_TIM4);

  LL_AHB4_GRP1_EnableClock(LL_AHB4_GRP1_PERIPH_GPIOB);
  LL_AHB4_GRP1_EnableClock(LL_AHB4_GRP1_PERIPH_GPIOD);
  /**TIM4 GPIO Configuration
  PB7   ------> TIM4_CH2
  PD12   ------> TIM4_CH1
  */
  GPIO_InitStruct.Pin = LL_GPIO_PIN_7;
  GPIO_InitStruct.Mode = LL_GPIO_MODE_ALTERNATE;
  GPIO_InitStruct.Speed = LL_GPIO_SPEED_FREQ_LOW;
  GPIO_InitStruct.OutputType = LL_GPIO_OUTPUT_PUSHPULL;
  GPIO_InitStruct.Pull = LL_GPIO_PULL_NO;
  GPIO_InitStruct.Alternate = LL_GPIO_AF_2;
  LL_GPIO_Init(GPIOB, &GPIO_InitStruct);

  GPIO_InitStruct.Pin = LL_GPIO_PIN_12;
  GPIO_InitStruct.Mode = LL_GPIO_MODE_ALTERNATE;
  GPIO_InitStruct.Speed = LL_GPIO_SPEED_FREQ_LOW;
  GPIO_InitStruct.OutputType = LL_GPIO_OUTPUT_PUSHPULL;
  GPIO_InitStruct.Pull = LL_GPIO_PULL_NO;
  GPIO_InitStruct.Alternate = LL_GPIO_AF_2;
  LL_GPIO_Init(GPIOD, &GPIO_InitStruct);

  TIM_InitStruct.Prescaler = 0;
  TIM_InitStruct.CounterMode = LL_TIM_COUNTERMODE_UP;
  TIM_InitStruct.Autoreload = 65535;
  TIM_InitStruct.ClockDivision = LL_TIM_CLOCKDIVISION_DIV1;
  LL_TIM_Init(TIM4, &TIM_InitStruct);
  LL_TIM_DisableARRPreload(TIM4);
  LL_TIM_SetEncoderMode(TIM4, LL_TIM_ENCODERMODE_X2_TI1);
  LL_TIM_IC_SetActiveInput(TIM4, LL_TIM_CHANNEL_CH1, LL_TIM_ACTIVEINPUT_DIRECTTI);
  LL_TIM_IC_SetPrescaler(TIM4, LL_TIM_CHANNEL_CH1, LL_TIM_ICPSC_DIV1);
  LL_TIM_IC_SetFilter(TIM4, LL_TIM_CHANNEL_CH1, LL_TIM_IC_FILTER_FDIV1);
  LL_TIM_IC_SetPolarity(TIM4, LL_TIM_CHANNEL_CH1, LL_TIM_IC_POLARITY_RISING);
  LL_TIM_IC_SetActiveInput(TIM4, LL_TIM_CHANNEL_CH2, LL_TIM_ACTIVEINPUT_DIRECTTI);
  LL_TIM_IC_SetPrescaler(TIM4, LL_TIM_CHANNEL_CH2, LL_TIM_ICPSC_DIV1);
  LL_TIM_IC_SetFilter(TIM4, LL_TIM_CHANNEL_CH2, LL_TIM_IC_FILTER_FDIV1);
  LL_TIM_IC_SetPolarity(TIM4, LL_TIM_CHANNEL_CH2, LL_TIM_IC_POLARITY_RISING);
  LL_TIM_SetTriggerOutput(TIM4, LL_TIM_TRGO_RESET);
  LL_TIM_DisableMasterSlaveMode(TIM4);
  /* USER CODE BEGIN TIM4_Init 2 */
    LL_TIM_EnableCounter(TIM4);
  /* USER CODE END TIM4_Init 2 */

}

static void MX_GPIO_Init(void)
{
  LL_GPIO_InitTypeDef GPIO_InitStruct = {0};

  /* GPIO Ports Clock Enable */
  LL_AHB4_GRP1_EnableClock(LL_AHB4_GRP1_PERIPH_GPIOK);
  LL_AHB4_GRP1_EnableClock(LL_AHB4_GRP1_PERIPH_GPIOG);
  LL_AHB4_GRP1_EnableClock(LL_AHB4_GRP1_PERIPH_GPIOD);
  LL_AHB4_GRP1_EnableClock(LL_AHB4_GRP1_PERIPH_GPIOC);
  LL_AHB4_GRP1_EnableClock(LL_AHB4_GRP1_PERIPH_GPIOA);
  LL_AHB4_GRP1_EnableClock(LL_AHB4_GRP1_PERIPH_GPIOB);
  LL_AHB4_GRP1_EnableClock(LL_AHB4_GRP1_PERIPH_GPIOJ);
  LL_AHB4_GRP1_EnableClock(LL_AHB4_GRP1_PERIPH_GPIOI);
  LL_AHB4_GRP1_EnableClock(LL_AHB4_GRP1_PERIPH_GPIOH);
  LL_AHB4_GRP1_EnableClock(LL_AHB4_GRP1_PERIPH_GPIOF);

  /**/
  LL_GPIO_SetOutputPin(GPIOG, CS_SPI_ETH_Pin|USB_POWER_Pin);

  /**/
  LL_GPIO_SetOutputPin(GPIOD, LED3_Pin|LED4_Pin|LCD_ENABLE_Pin);

  /**/
  LL_GPIO_SetOutputPin(CS_SPI_EEPROM_GPIO_Port, CS_SPI_EEPROM_Pin);

  /**/
  LL_GPIO_SetOutputPin(LED_ENABLE_GPIO_Port, LED_ENABLE_Pin);

  /**/
  LL_GPIO_SetOutputPin(GPIOA, LCD_RESET_Pin|PB_COL3_Pin|PB_COL2_Pin|PB_COL0_Pin
                          |PB_COL1_Pin);

  /**/
  LL_GPIO_ResetOutputPin(LCD_BACKLIGHT_GPIO_Port, LCD_BACKLIGHT_Pin);

  /**/
  GPIO_InitStruct.Pin = CS_SPI_ETH_Pin|USB_POWER_Pin;
  GPIO_InitStruct.Mode = LL_GPIO_MODE_OUTPUT;
  GPIO_InitStruct.Speed = LL_GPIO_SPEED_FREQ_LOW;
  GPIO_InitStruct.OutputType = LL_GPIO_OUTPUT_PUSHPULL;
  GPIO_InitStruct.Pull = LL_GPIO_PULL_NO;
  LL_GPIO_Init(GPIOG, &GPIO_InitStruct);

  /**/
  GPIO_InitStruct.Pin = LED3_Pin|LED4_Pin|LCD_ENABLE_Pin;
  GPIO_InitStruct.Mode = LL_GPIO_MODE_OUTPUT;
  GPIO_InitStruct.Speed = LL_GPIO_SPEED_FREQ_LOW;
  GPIO_InitStruct.OutputType = LL_GPIO_OUTPUT_PUSHPULL;
  GPIO_InitStruct.Pull = LL_GPIO_PULL_NO;
  LL_GPIO_Init(GPIOD, &GPIO_InitStruct);

  /**/
  GPIO_InitStruct.Pin = PB_ROW0_Pin|PB_ROW2_Pin|PB_ROW3_Pin|PB_ROW1_Pin;
  GPIO_InitStruct.Mode = LL_GPIO_MODE_INPUT;
  GPIO_InitStruct.Pull = LL_GPIO_PULL_NO;
  LL_GPIO_Init(GPIOC, &GPIO_InitStruct);

  /**/
  GPIO_InitStruct.Pin = CS_SPI_EEPROM_Pin;
  GPIO_InitStruct.Mode = LL_GPIO_MODE_OUTPUT;
  GPIO_InitStruct.Speed = LL_GPIO_SPEED_FREQ_LOW;
  GPIO_InitStruct.OutputType = LL_GPIO_OUTPUT_PUSHPULL;
  GPIO_InitStruct.Pull = LL_GPIO_PULL_NO;
  LL_GPIO_Init(CS_SPI_EEPROM_GPIO_Port, &GPIO_InitStruct);

  /**/
  GPIO_InitStruct.Pin = LED_ENABLE_Pin;
  GPIO_InitStruct.Mode = LL_GPIO_MODE_OUTPUT;
  GPIO_InitStruct.Speed = LL_GPIO_SPEED_FREQ_LOW;
  GPIO_InitStruct.OutputType = LL_GPIO_OUTPUT_PUSHPULL;
  GPIO_InitStruct.Pull = LL_GPIO_PULL_NO;
  LL_GPIO_Init(LED_ENABLE_GPIO_Port, &GPIO_InitStruct);

  /**/
  GPIO_InitStruct.Pin = LCD_RESET_Pin|LCD_BACKLIGHT_Pin;
  GPIO_InitStruct.Mode = LL_GPIO_MODE_OUTPUT;
  GPIO_InitStruct.Speed = LL_GPIO_SPEED_FREQ_LOW;
  GPIO_InitStruct.OutputType = LL_GPIO_OUTPUT_PUSHPULL;
  GPIO_InitStruct.Pull = LL_GPIO_PULL_NO;
  LL_GPIO_Init(GPIOA, &GPIO_InitStruct);

  /**/
  GPIO_InitStruct.Pin = LL_GPIO_PIN_12|LL_GPIO_PIN_11;
  GPIO_InitStruct.Mode = LL_GPIO_MODE_ALTERNATE;
  GPIO_InitStruct.Speed = LL_GPIO_SPEED_FREQ_MEDIUM;
  GPIO_InitStruct.OutputType = LL_GPIO_OUTPUT_PUSHPULL;
  GPIO_InitStruct.Pull = LL_GPIO_PULL_NO;
  GPIO_InitStruct.Alternate = LL_GPIO_AF_10;
  LL_GPIO_Init(GPIOA, &GPIO_InitStruct);

  /**/
  GPIO_InitStruct.Pin = PB_COL3_Pin|PB_COL2_Pin|PB_COL0_Pin|PB_COL1_Pin;
  GPIO_InitStruct.Mode = LL_GPIO_MODE_OUTPUT;
  GPIO_InitStruct.Speed = LL_GPIO_SPEED_FREQ_LOW;
  GPIO_InitStruct.OutputType = LL_GPIO_OUTPUT_OPENDRAIN;
  GPIO_InitStruct.Pull = LL_GPIO_PULL_NO;
  LL_GPIO_Init(GPIOA, &GPIO_InitStruct);

  /**/
  GPIO_InitStruct.Pin = ENCODER1_BTN_Pin|ENCODER0_BTN_Pin;
  GPIO_InitStruct.Mode = LL_GPIO_MODE_INPUT;
  GPIO_InitStruct.Pull = LL_GPIO_PULL_NO;
  LL_GPIO_Init(GPIOB, &GPIO_InitStruct);

}

/* USER CODE BEGIN 4 */
void ITM_Init(void) {

    GPIO_InitTypeDef GPIO_InitStruct;
    GPIO_InitStruct.Pin = GPIO_PIN_3;
    GPIO_InitStruct.Mode = GPIO_MODE_AF_PP;
    GPIO_InitStruct.Pull = GPIO_NOPULL;
    GPIO_InitStruct.Speed = GPIO_SPEED_FREQ_VERY_HIGH;
    GPIO_InitStruct.Alternate = GPIO_AF0_TRACE;
    HAL_GPIO_Init(GPIOB, &GPIO_InitStruct);

    // Enable trace in Core Debug
    CoreDebug->DEMCR |= CoreDebug_DEMCR_TRCENA_Msk;

    // Unlock ITM
    ITM->LAR = 0xC5ACCE55;

    // Enable ITM
    ITM->TCR = (1 << ITM_TCR_ITMENA_Pos) |  // Enable ITM
               (1 << ITM_TCR_SYNCENA_Pos); // Enable sync packets

    // Enable stimulus port 0
    ITM->TER = 0x1;

}

/* USER CODE END 4 */

void Error_Handler(void)
{
  __disable_irq();
  while (1)
  {
  }
}
